VERSION ""

NS_ :

BS_:

BU_: XXX

BO_ 85 CID_LGVWZI: 8 XXX
 SG_ sig_elmjsl : 40|1@1+ (1,0) [0|1] "" XXX
 SG_ sig_dfuiap : 56|8@1+ (1,0) [0|255] "" XXX

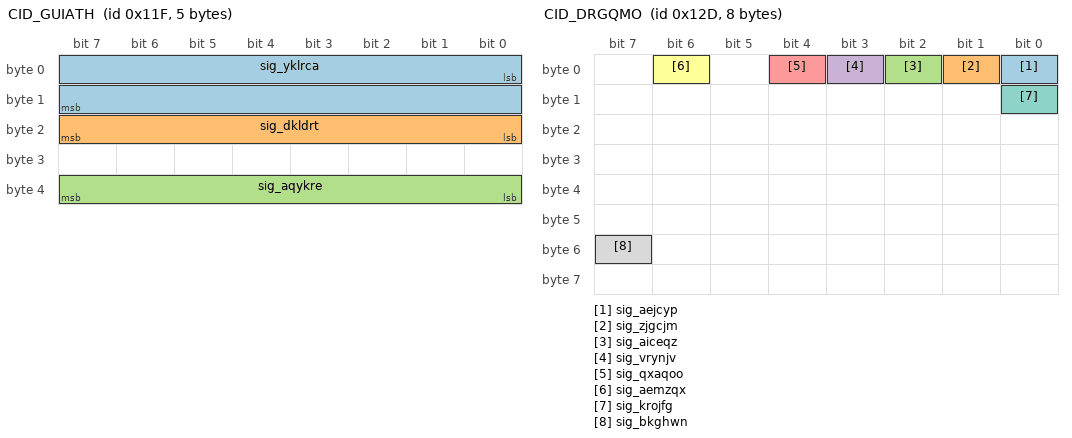
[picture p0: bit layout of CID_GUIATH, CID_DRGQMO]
BO_ 287 CID_GUIATH: 5 XXX
 SG_ sig_yklrca : 0|16@1- (0.1,0) [-450|450] "" XXX
 SG_ sig_dkldrt : 16|8@1+ (4,0) [0|1020] "" XXX
 SG_ sig_aqykre : 32|8@1+ (1,0) [0|255] "" XXX

BO_ 289 CID_AXTNLW: 8 XXX
 SG_ sig_urzjov : 0|12@1+ (1,0) [0|255] "" XXX

BO_ 301 CID_DRGQMO: 8 XXX
 SG_ sig_aejcyp : 0|1@0+ (1,0) [0|1] "" XXX
 SG_ sig_zjgcjm : 1|1@0+ (1,0) [0|1] "" XXX
 SG_ sig_aiceqz : 2|1@0+ (1,0) [0|1] "" XXX
 SG_ sig_vrynjv : 3|1@0+ (1,0) [0|1] "" XXX
 SG_ sig_qxaqoo : 4|1@0+ (1,0) [0|1] "" XXX
 SG_ sig_aemzqx : 6|1@0+ (1,0) [0|1] "" XXX
 SG_ sig_krojfg : 8|1@0+ (1,0) [0|1] "" XXX
 SG_ sig_bkghwn : 55|1@0+ (1,0) [0|1] "" XXX

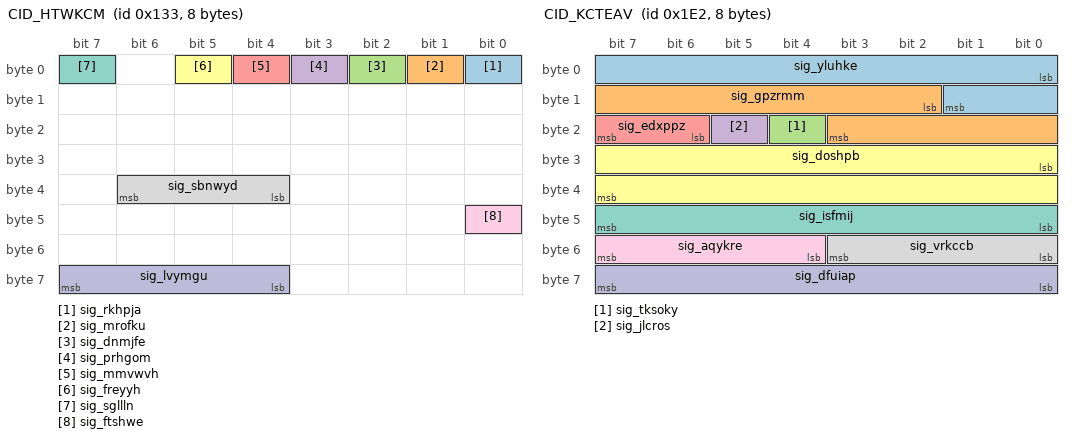
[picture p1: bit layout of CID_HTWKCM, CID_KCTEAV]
BO_ 307 CID_HTWKCM: 8 XXX
 SG_ sig_rkhpja : 0|1@0+ (1,0) [0|1] "" XXX
 SG_ sig_mrofku : 1|1@1+ (1,0) [0|1] "" XXX
 SG_ sig_dnmjfe : 2|1@1+ (1,0) [0|1] "" XXX
 SG_ sig_prhgom : 3|1@1+ (1,0) [0|1] "" XXX
 SG_ sig_mmvwvh : 4|1@0+ (1,0) [0|1] "" XXX
 SG_ sig_freyyh : 5|1@0+ (1,0) [0|1] "" XXX
 SG_ sig_sgllln : 7|1@0+ (1,0) [0|1] "" XXX
 SG_ sig_sbnwyd : 36|3@1+ (1,0) [0|7] "" XXX
 SG_ sig_ftshwe : 40|1@0+ (1,0) [0|1] "" XXX
 SG_ sig_lvymgu : 63|4@0+ (1,0) [0|15] "" XXX

BO_ 482 CID_KCTEAV: 8 XXX
 SG_ sig_yluhke : 0|10@1- (0.01,0) [0|5] "" XXX
 SG_ sig_gpzrmm : 10|10@1- (0.01,0) [-5|0] "" XXX
 SG_ sig_tksoky : 20|1@0+ (1,0) [0|1] "" XXX
 SG_ sig_jlcros : 21|1@0+ (1,0) [0|1] "" XXX
 SG_ sig_edxppz : 22|2@1+ (1,0) [0|1] "" XXX
 SG_ sig_doshpb : 24|16@1- (0.1,0) [-780|779.9] "" XXX
 SG_ sig_isfmij : 47|8@0+ (1,0) [0|255] "" XXX
 SG_ sig_vrkccb : 48|4@1+ (1,0) [0|15] "" XXX
 SG_ sig_aqykre : 52|4@1+ (1,0) [0|15] "" XXX
 SG_ sig_dfuiap : 56|8@1+ (1,0) [0|255] "" XXX

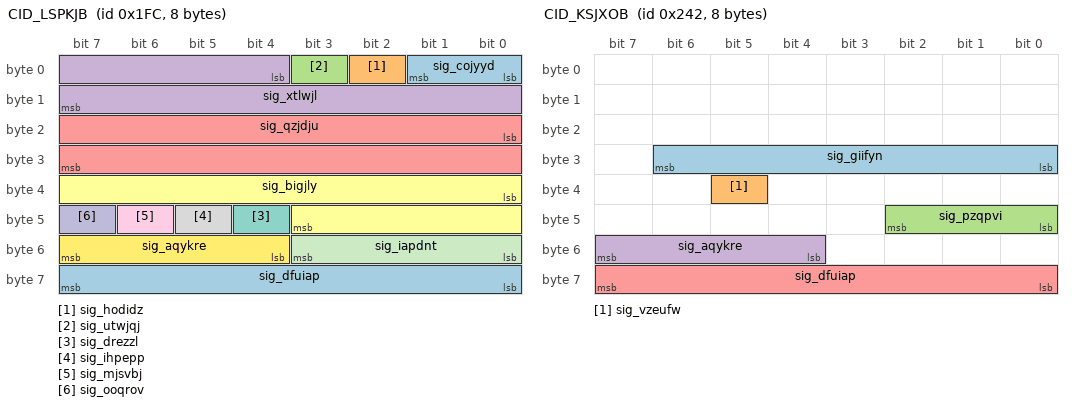
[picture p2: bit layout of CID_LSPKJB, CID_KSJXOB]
BO_ 508 CID_LSPKJB: 8 XXX
 SG_ sig_cojyyd : 0|2@1+ (1,0) [0|1] "" XXX
 SG_ sig_hodidz : 2|1@1+ (1,0) [0|1] "" XXX
 SG_ sig_utwjqj : 3|1@0+ (1,0) [0|1] "" XXX
 SG_ sig_xtlwjl : 4|12@1- (1,0) [-2048|2047] "" XXX
 SG_ sig_qzjdju : 16|16@1- (0.1,0) [-780|779.9] "Deg" XXX
 SG_ sig_bigjly : 32|12@1- (0.01,0) [0|63] "" XXX
 SG_ sig_drezzl : 44|1@0+ (1,0) [0|1] "" XXX
 SG_ sig_ihpepp : 45|1@1+ (1,0) [0|255] "" XXX
 SG_ sig_mjsvbj : 46|1@1+ (1,0) [0|1] "" XXX
 SG_ sig_ooqrov : 47|1@0+ (1,0) [0|3] "" XXX
 SG_ sig_iapdnt : 48|4@1+ (1,0) [0|15] "" XXX
 SG_ sig_aqykre : 52|4@1+ (1,0) [0|15] "" XXX
 SG_ sig_dfuiap : 56|8@1+ (1,0) [0|255] "" XXX

BO_ 578 CID_KSJXOB: 8 XXX
 SG_ sig_giifyn : 30|7@0+ (1,0) [0|127] "" XXX
 SG_ sig_vzeufw : 37|1@0+ (1,0) [0|1] "" XXX
 SG_ sig_pzqpvi : 40|3@1+ (1,0) [0|7] "" XXX
 SG_ sig_aqykre : 55|4@0+ (1,0) [0|15] "" XXX
 SG_ sig_dfuiap : 56|8@1+ (1,0) [0|255] "" XXX

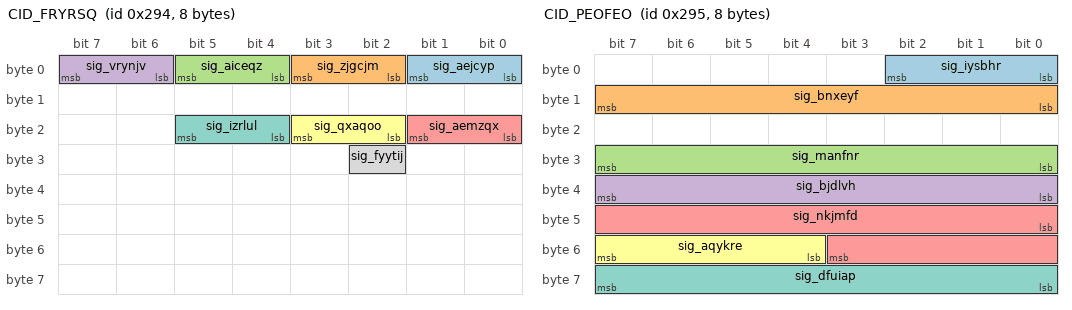
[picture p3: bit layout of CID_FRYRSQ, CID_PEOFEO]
BO_ 660 CID_FRYRSQ: 8 XXX
 SG_ sig_aejcyp : 1|2@0+ (1,0) [0|3] "" XXX
 SG_ sig_zjgcjm : 3|2@0+ (1,0) [0|3] "" XXX
 SG_ sig_aiceqz : 5|2@0+ (1,0) [0|3] "" XXX
 SG_ sig_vrynjv : 7|2@0+ (1,0) [0|3] "" XXX
 SG_ sig_aemzqx : 17|2@0+ (1,0) [0|3] "" XXX
 SG_ sig_qxaqoo : 19|2@0+ (1,0) [0|3] "" XXX
 SG_ sig_izrlul : 21|2@0+ (1,0) [0|3] "" XXX
 SG_ sig_fyytij : 26|1@0+ (1,0) [0|1] "" XXX

BO_ 661 CID_PEOFEO: 8 XXX
 SG_ sig_iysbhr : 2|3@0+ (1,0) [0|7] "" XXX
 SG_ sig_bnxeyf : 15|8@0+ (1,0) [0|255] "" XXX
 SG_ sig_manfnr : 31|8@0+ (1,0) [0|255] "" XXX
 SG_ sig_bjdlvh : 32|8@1+ (1,0) [0|255] "" XXX
 SG_ sig_nkjmfd : 40|12@1+ (1,0) [0|255] "" XXX
 SG_ sig_aqykre : 52|4@1+ (1,0) [0|15] "" XXX
 SG_ sig_dfuiap : 63|8@0+ (1,0) [0|255] "" XXX

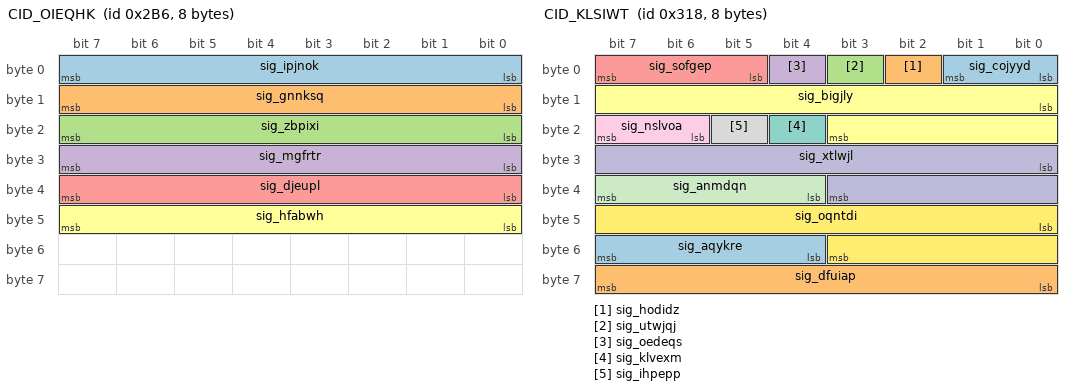
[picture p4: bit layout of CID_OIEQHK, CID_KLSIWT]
BO_ 694 CID_OIEQHK: 8 XXX
 SG_ sig_ipjnok : 7|8@0+ (1,0) [0|255] "" XXX
 SG_ sig_gnnksq : 15|8@0+ (1,0) [0|255] "" XXX
 SG_ sig_zbpixi : 23|8@0+ (1,0) [0|255] "" XXX
 SG_ sig_mgfrtr : 31|8@0+ (1,0) [0|255] "" XXX
 SG_ sig_djeupl : 39|8@0+ (1,0) [0|255] "" XXX
 SG_ sig_hfabwh : 47|8@0+ (1,0) [0|255] "" XXX

BO_ 790 CID_CBWZAL: 8 XXX
 SG_ sig_hhbzqk : 3|4@0+ (1,0) [0|1] "" XXX
 SG_ sig_aubcyb : 4|2@1+ (1,0) [0|3] "" XXX
 SG_ sig_twqvrv : 6|2@1+ (1,0) [0|3] "" XXX
 SG_ sig_wzdgcr : 8|2@1+ (1,0) [0|3] "" XXX
 SG_ sig_ahmuwn : 10|1@1+ (1,0) [0|1] "" XXX
 SG_ sig_rtqgmc : 11|4@1+ (1,0) [0|1] "" XXX
 SG_ sig_mxkwfo : 15|1@0+ (1,0) [0|1] "" XXX
 SG_ sig_doshpb : 16|11@1- (1,0) [-1024|1023] "" XXX
 SG_ sig_tksoky : 27|1@1+ (1,0) [0|1] "" XXX
 SG_ sig_jlcros : 28|1@1+ (1,0) [0|3] "" XXX
 SG_ sig_jtvfur : 29|1@0+ (1,0) [0|1] "" XXX
 SG_ sig_mnjjpp : 30|1@0+ (1,0) [0|1] "" XXX
 SG_ sig_vmparo : 31|1@0+ (1,0) [0|1] "" XXX
 SG_ sig_tvloje : 32|2@1+ (1,0) [0|3] "" XXX
 SG_ sig_ejfbzf : 34|2@1+ (1,0) [0|3] "" XXX
 SG_ sig_dkuhza : 36|4@1+ (1,0) [0|3] "" XXX
 SG_ sig_sahect : 40|8@1+ (5,-5) [-5|1270] "" XXX
 SG_ sig_itivad : 49|2@0+ (1,0) [0|3] "" XXX
 SG_ sig_bilqmj : 51|2@0+ (1,0) [0|3] "" XXX
 SG_ sig_aqykre : 52|4@1+ (1,0) [0|15] "" XXX
 SG_ sig_dfuiap : 56|8@1+ (1,0) [0|15] "" XXX

BO_ 792 CID_KLSIWT: 8 XXX
 SG_ sig_cojyyd : 0|2@1+ (1,0) [0|1] "" XXX
 SG_ sig_hodidz : 2|1@1+ (1,0) [0|1] "" XXX
 SG_ sig_utwjqj : 3|1@1+ (1,0) [0|1] "" XXX
 SG_ sig_oedeqs : 4|1@1+ (1,0) [0|1] "" XXX
 SG_ sig_sofgep : 5|3@1+ (1,0) [0|1] "" XXX
 SG_ sig_bigjly : 8|12@1- (1,0) [-2048|2047] "" XXX
 SG_ sig_klvexm : 20|1@1+ (1,0) [0|1] "" XXX
 SG_ sig_ihpepp : 21|1@1+ (1,0) [0|1] "" XXX
 SG_ sig_nslvoa : 22|2@1+ (1,0) [0|15] "" XXX
 SG_ sig_xtlwjl : 24|12@1- (1,0) [-2048|2047] "" XXX
 SG_ sig_anmdqn : 36|4@1+ (1,0) [0|15] "" XXX
 SG_ sig_oqntdi : 40|12@1+ (1,0) [0|4095] "" XXX
 SG_ sig_aqykre : 52|4@1+ (1,0) [0|15] "" XXX
 SG_ sig_dfuiap : 56|8@1+ (1,0) [0|255] "" XXX

BO_ 813 CID_IFEBMH: 8 XXX
 SG_ sig_sxtbyo : 0|9@1+ (0.5,0) [0|255.5] "" XXX
 SG_ sig_hsutif : 9|1@1+ (1,0) [0|1] "" XXX
 SG_ sig_gudtut : 10|3@1+ (1,0) [0|7] "" XXX
 SG_ sig_eakppe : 13|3@1+ (1,0) [0|7] "" XXX
 SG_ sig_vrjjwz : 16|1@1+ (1,0) [0|1] "" XXX
 SG_ sig_prdgny : 17|1@1+ (1,0) [0|1] "" XXX
 SG_ sig_utwjqj : 18|1@1+ (1,0) [0|1] "" XXX
 SG_ sig_ltxxsc : 19|3@1+ (1,0) [0|1] "" XXX
 SG_ sig_imiurt : 22|1@0+ (1,0) [0|1] "" XXX
 SG_ sig_erlxov : 23|1@0+ (1,0) [0|1] "" XXX
 SG_ sig_wzdgcr : 24|1@1+ (1,0) [0|1] "" XXX
 SG_ sig_zyvuem : 25|7@1+ (1,0) [0|127] "" XXX
 SG_ sig_qytpng : 32|4@1+ (1,0) [0|15] "" XXX
 SG_ sig_vbdgme : 36|12@1+ (1,0) [0|4095] "" XXX
 SG_ sig_aqykre : 48|4@1+ (1,0) [0|15] "" XXX
 SG_ sig_zcboia : 55|4@0+ (1,0) [0|15] "" XXX
 SG_ sig_dfuiap : 56|8@1+ (1,0) [0|255] "" XXX

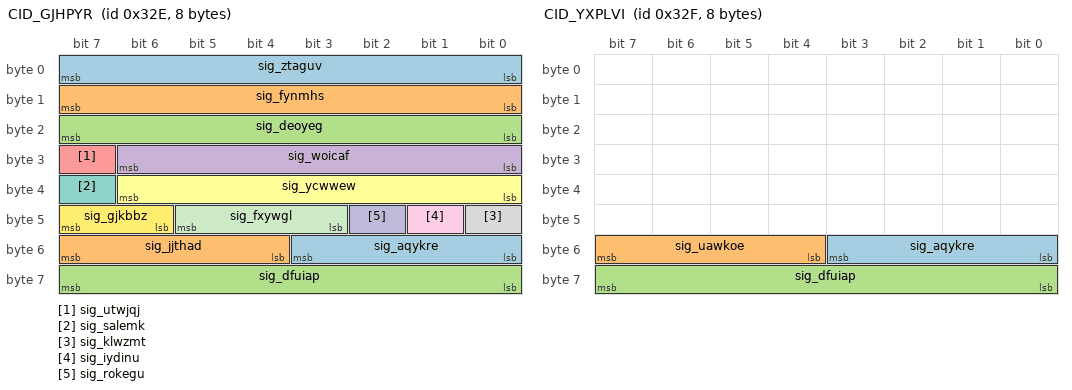
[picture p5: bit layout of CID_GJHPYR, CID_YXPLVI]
BO_ 814 CID_GJHPYR: 8 XXX
 SG_ sig_ztaguv : 0|8@1+ (0.05,-5) [-100|155] "" XXX
 SG_ sig_fynmhs : 8|8@1+ (0.05,-5) [0|1.26] "" XXX
 SG_ sig_deoyeg : 16|8@1+ (0.05,-5) [0|1.26] "" XXX
 SG_ sig_woicaf : 24|7@1+ (0.2,0) [0|12.7] "" XXX
 SG_ sig_utwjqj : 31|1@0+ (1,0) [0|1] "" XXX
 SG_ sig_ycwwew : 32|7@1+ (0.2,-16) [0|12.7] "" XXX
 SG_ sig_salemk : 39|1@0+ (1,0) [0|1] "" XXX
 SG_ sig_klwzmt : 40|1@0+ (1,0) [0|1] "" XXX
 SG_ sig_iydinu : 41|1@0+ (1,0) [0|1] "" XXX
 SG_ sig_rokegu : 42|1@1+ (1,0) [0|3] "" XXX
 SG_ sig_fxywgl : 45|3@0+ (1,0) [0|1] "" XXX
 SG_ sig_gjkbbz : 46|2@1+ (1,0) [0|3] "" XXX
 SG_ sig_aqykre : 48|4@1+ (1,0) [0|15] "" XXX
 SG_ sig_jjthad : 55|4@0+ (1,0) [0|15] "" XXX
 SG_ sig_dfuiap : 56|8@1+ (1,0) [0|255] "" XXX

BO_ 815 CID_YXPLVI: 8 XXX
 SG_ sig_aqykre : 48|4@1+ (1,0) [0|15] "" XXX
 SG_ sig_uawkoe : 55|4@0+ (1,0) [0|15] "" XXX
 SG_ sig_dfuiap : 56|8@1+ (1,0) [0|255] "" XXX

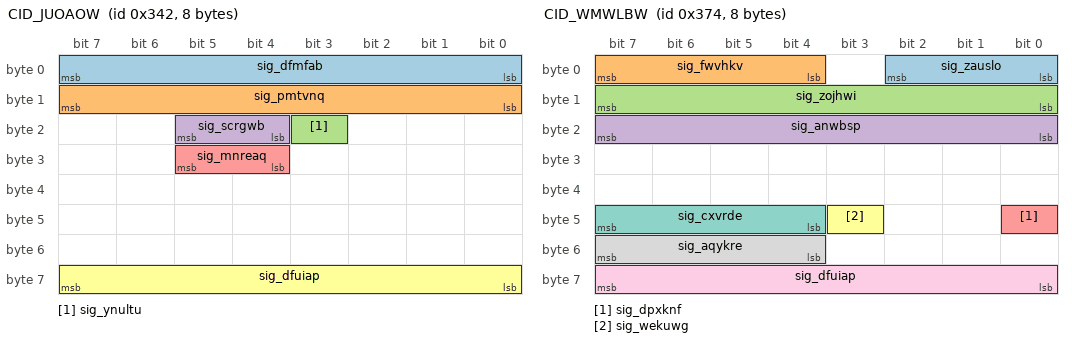
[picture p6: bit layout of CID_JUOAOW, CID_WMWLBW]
BO_ 834 CID_JUOAOW: 8 XXX
 SG_ sig_dfmfab : 0|8@1+ (0.01,0) [0|2.55] "" XXX
 SG_ sig_pmtvnq : 8|8@1+ (0.01,0) [0|2.55] "" XXX
 SG_ sig_ynultu : 19|1@1+ (1,0) [0|1] "" XXX
 SG_ sig_scrgwb : 20|2@1+ (1,0) [0|255] "" XXX
 SG_ sig_mnreaq : 28|2@1+ (1,0) [0|1] "" XXX
 SG_ sig_dfuiap : 56|8@1+ (1,0) [0|255] "" XXX

 BO_ 884 CID_WMWLBW: 8 MRR
 SG_ sig_zauslo : 2|3@0+ (1,0) [0|3] "" MRR
 SG_ sig_fwvhkv : 7|4@0+ (1,0) [0|15] "" MRR
 SG_ sig_zojhwi : 15|8@0+ (0.1,-12) [0|255] "" MRR
 SG_ sig_anwbsp : 23|8@0+ (1,-100) [0|255] "" MRR
 SG_ sig_dpxknf : 40|1@0+ (1,0) [0|3] "" MRR
 SG_ sig_wekuwg : 43|1@0+ (1,0) [0|1] "" XXX
 SG_ sig_cxvrde : 44|4@1+ (1,0) [0|15] "" XXX
 SG_ sig_aqykre : 52|4@1+ (1,0) [0|15] "" MRR
 SG_ sig_dfuiap : 56|8@1+ (1,0) [0|255] "" MRR

BO_ 944 CID_NJBMII: 8 XXX
 SG_ sig_qupgha : 1|2@0+ (1,0) [0|3] "" XXX
 SG_ sig_jsaghf : 2|1@0+ (1,0) [0|1] "" XXX
 SG_ sig_lybfcb : 4|2@0+ (1,0) [0|3] "" XXX
 SG_ sig_xbvrvj : 5|1@0+ (1,0) [0|1] "" XXX
 SG_ sig_pcqspy : 6|1@0+ (1,0) [0|1] "" XXX
 SG_ sig_gngoys : 7|1@0+ (1,0) [0|1] "" XXX
 SG_ sig_ssvzal : 8|1@0+ (1,0) [0|1] "" XXX
 SG_ sig_rmhyuf : 11|3@0+ (1,0) [0|7] "" XXX
 SG_ sig_okrnhb : 12|1@0+ (1,0) [0|1] "" XXX
 SG_ sig_ewmohe : 14|2@0+ (1,0) [0|3] "" XXX
 SG_ sig_kbhqsx : 15|1@0+ (1,0) [0|1] "" XXX
 SG_ sig_uovryo : 16|1@0+ (1,0) [0|1] "" XXX
 SG_ sig_pvjlnv : 18|2@0+ (1,0) [0|3] "" XXX
 SG_ sig_adnvrh : 19|1@0+ (1,0) [0|1] "" XXX
 SG_ sig_wlfapb : 23|4@0+ (1,0) [0|15] "" XXX
 SG_ sig_iwztjh : 24|28@1+ (1,0) [0|268435455] "" XXX
 SG_ sig_aqykre : 52|4@1+ (1,0) [0|15] "" XXX
 SG_ sig_dfuiap : 56|8@1+ (1,0) [0|255] "" XXX

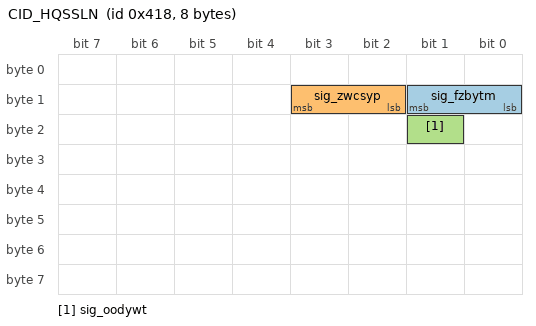
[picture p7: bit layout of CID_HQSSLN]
BO_ 1048 CID_HQSSLN: 8 XXX
 SG_ sig_fzbytm : 9|2@0+ (1,0) [0|1] "" XXX
 SG_ sig_zwcsyp : 11|2@0+ (1,0) [0|1] "" XXX
 SG_ sig_oodywt : 17|1@0+ (1,0) [0|1] "" XXX

VAL_ 578 sig_pzqpvi 4 "D" 2 "R" 3 "N" 1 "P";
VAL_ 790 sig_hhbzqk 11 "AutoFullBeamActive" 2 "AutoFullBeamInactive";
VAL_ 790 sig_aubcyb 0 "GRAY" 1 "GREEN" 2 "YELLOW" 3 "RED";
VAL_ 790 sig_twqvrv 3 "ALARM_AND_LKA" 2 "LKA" 1 "ALARM" 0 "DISABLE";
VAL_ 790 sig_ejfbzf 0 "GRAY" 1 "GREEN" 2 "YELLOW" 3 "RED";
VAL_ 790 sig_itivad 0 "VIBRATION" 1 "AUDIO" 2 "AUDIO_AND_VIBRATION";
VAL_ 792 sig_cojyyd 0 "NotReady" 1 "Ready" 2 "Active" 3 "TemporaryFail";
VAL_ 813 sig_gudtut 4 "4BAR" 3 "3BAR" 2 "2BAR" 1 "1BAR";
VAL_ 813 sig_ltxxsc 0 "OFF" 2 "ACC_ON" 3 "ACC_ACTIVE" 5 "FORCE_ACCEL" 7 "ERROR";
VAL_ 813 sig_zyvuem 36 "ACC_ERROR" 22 "OVERRIDE" 12 "ENGAGE" 8 "DISENGAGE" 20 "ACC_ON" 32 "ACC_OFF" 48 "CHECK_GEAR_D" 16 "FORCE_ACCEL" 0 "NONE";
VAL_ 814 sig_fxywgl 0 "Off" 1 "Passive" 2 "StandBy" 3 "ActiveControl" 4 "BrakeOnly" 5 "Override" 6 "Standstill" 7 "Failure";
VAL_ 814 sig_gjkbbz 0 "Softoff" 1 "Fastoff" 2 "Immediateoff" 3 "Initial";
VAL_ 834 sig_scrgwb 2 "SPORT" 1 "ECO" 0 "SNOW";
VAL_ 834 sig_mnreaq 3 "HEV" 2 "FORCE_EV" 1 "EV";
VAL_ 944 sig_lybfcb 0 "NOTPRESSED" 1 "DOWN_SETSPEED" 3 "UP_RESETSPEED";
